# NPCX498S register map
File version: 1.0
Registers are 8-bit, read-write, reset 0x0 unless marked. A register's access mark holds for its fields unless they carry their own. Offsets are from the block's base; [hi:lo] are bit positions; {n}, {i} and the like mark numbered series.

## OTPI
Base 0x40007000
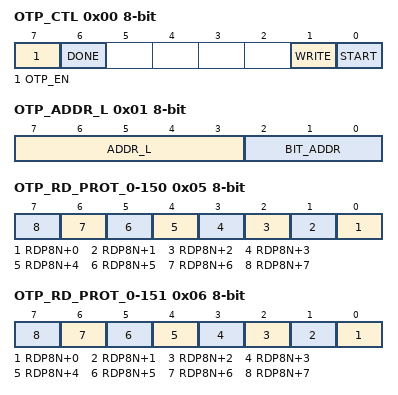
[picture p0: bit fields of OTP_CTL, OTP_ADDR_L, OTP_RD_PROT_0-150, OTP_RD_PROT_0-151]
0x00 OTP_CTL — OTP Control Register (OTP_CTL)
  [7] OTP_EN — OTPI Module Enable
  [6] DONE — OTP Operation Completed
  [1] WRITE — Write Select
  [0] START — Start OTP Operation
0x01 OTP_ADDR_L — OTP Address Low Register (OTP_ADDR_L)
  [7:3] ADDR_L — OTP Byte Address Low
  [2:0] BIT_ADDR — OTP Bit Address
0x02 OTP_ADDR_H — OTP Address High Register (OTP_ADDR_H)
  [5:0] ADDR_H — OTP Byte Address High
0x03 OTP_DOUT — OTP Read Data Register (OTP_DOUT)
0x05 OTP_RD_PROT_0-150 — OTP Read Protect 0-15 Register (OTP_RD_PROT_0-15)
  [n] RDP8N+{n} (n=0..7) — Read Protect Block 8*n+{n}
0x06 OTP_RD_PROT_0-151 — OTP Read Protect 0-15 Register (OTP_RD_PROT_0-15)
  [n] RDP8N+{n} (n=0..7) — Read Protect Block 8*n+{n}
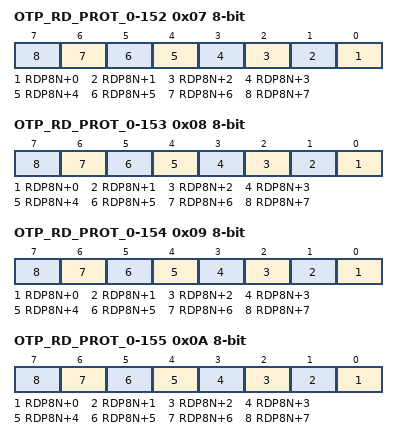
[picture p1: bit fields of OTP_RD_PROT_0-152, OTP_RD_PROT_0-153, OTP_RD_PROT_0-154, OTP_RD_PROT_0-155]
0x07 OTP_RD_PROT_0-152 — OTP Read Protect 0-15 Register (OTP_RD_PROT_0-15)
  [n] RDP8N+{n} (n=0..7) — Read Protect Block 8*n+{n}
0x08 OTP_RD_PROT_0-153 — OTP Read Protect 0-15 Register (OTP_RD_PROT_0-15)
  [n] RDP8N+{n} (n=0..7) — Read Protect Block 8*n+{n}
0x09 OTP_RD_PROT_0-154 — OTP Read Protect 0-15 Register (OTP_RD_PROT_0-15)
  [n] RDP8N+{n} (n=0..7) — Read Protect Block 8*n+{n}
0x0A OTP_RD_PROT_0-155 — OTP Read Protect 0-15 Register (OTP_RD_PROT_0-15)
  [n] RDP8N+{n} (n=0..7) — Read Protect Block 8*n+{n}
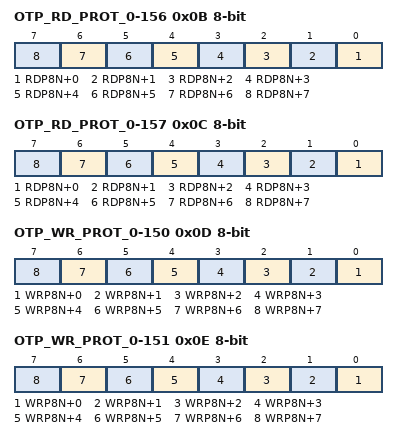
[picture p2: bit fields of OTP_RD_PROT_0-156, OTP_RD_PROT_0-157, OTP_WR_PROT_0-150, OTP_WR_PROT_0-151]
0x0B OTP_RD_PROT_0-156 — OTP Read Protect 0-15 Register (OTP_RD_PROT_0-15)
  [n] RDP8N+{n} (n=0..7) — Read Protect Block 8*n+{n}
0x0C OTP_RD_PROT_0-157 — OTP Read Protect 0-15 Register (OTP_RD_PROT_0-15)
  [n] RDP8N+{n} (n=0..7) — Read Protect Block 8*n+{n}
0x0D OTP_WR_PROT_0-150 — OTP Write Protect 0-15 Register (OTP_WR_PROT_0-15)
  [n] WRP8N+{n} (n=0..7) — Write Protect Block 8*n+{n}
0x0E OTP_WR_PROT_0-151 — OTP Write Protect 0-15 Register (OTP_WR_PROT_0-15)
  [n] WRP8N+{n} (n=0..7) — Write Protect Block 8*n+{n}
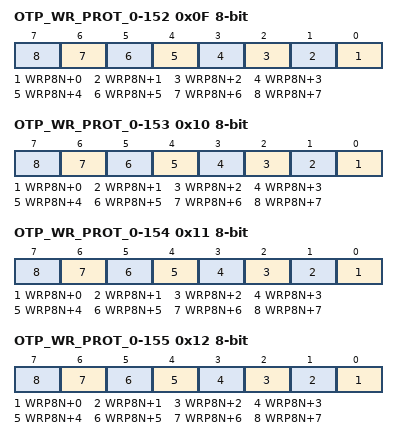
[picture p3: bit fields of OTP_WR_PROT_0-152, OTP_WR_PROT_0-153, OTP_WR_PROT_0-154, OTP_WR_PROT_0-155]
0x0F OTP_WR_PROT_0-152 — OTP Write Protect 0-15 Register (OTP_WR_PROT_0-15)
  [n] WRP8N+{n} (n=0..7) — Write Protect Block 8*n+{n}
0x10 OTP_WR_PROT_0-153 — OTP Write Protect 0-15 Register (OTP_WR_PROT_0-15)
  [n] WRP8N+{n} (n=0..7) — Write Protect Block 8*n+{n}
0x11 OTP_WR_PROT_0-154 — OTP Write Protect 0-15 Register (OTP_WR_PROT_0-15)
  [n] WRP8N+{n} (n=0..7) — Write Protect Block 8*n+{n}
0x12 OTP_WR_PROT_0-155 — OTP Write Protect 0-15 Register (OTP_WR_PROT_0-15)
  [n] WRP8N+{n} (n=0..7) — Write Protect Block 8*n+{n}
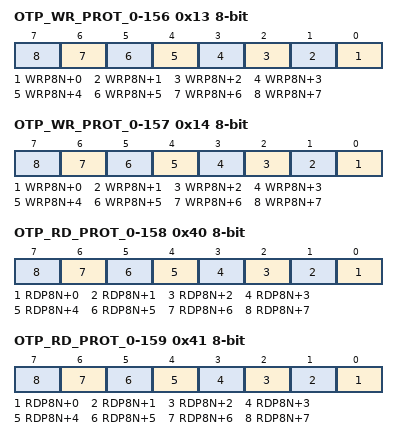
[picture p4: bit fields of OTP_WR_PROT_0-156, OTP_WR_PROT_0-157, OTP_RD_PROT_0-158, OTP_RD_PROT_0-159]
0x13 OTP_WR_PROT_0-156 — OTP Write Protect 0-15 Register (OTP_WR_PROT_0-15)
  [n] WRP8N+{n} (n=0..7) — Write Protect Block 8*n+{n}
0x14 OTP_WR_PROT_0-157 — OTP Write Protect 0-15 Register (OTP_WR_PROT_0-15)
  [n] WRP8N+{n} (n=0..7) — Write Protect Block 8*n+{n}
0x15 OTP_PRESC — OTP Prescaler Register (OTP_PRESC)
0x16 OTP_WRITE_EN0-30 — OTP Write Enable 0-3 Register (OTP_WRITE_EN0-3)
0x17 OTP_WRITE_EN0-31 — OTP Write Enable 0-3 Register (OTP_WRITE_EN0-3)
0x18 OTP_WRITE_EN0-32 — OTP Write Enable 0-3 Register (OTP_WRITE_EN0-3)
0x19 OTP_WRITE_EN0-33 — OTP Write Enable 0-3 Register (OTP_WRITE_EN0-3)
0x40 OTP_RD_PROT_0-158 — OTP Read Protect 0-15 Register (OTP_RD_PROT_0-15)
  [n] RDP8N+{n} (n=0..7) — Read Protect Block 8*n+{n}
0x41 OTP_RD_PROT_0-159 — OTP Read Protect 0-15 Register (OTP_RD_PROT_0-15)
  [n] RDP8N+{n} (n=0..7) — Read Protect Block 8*n+{n}
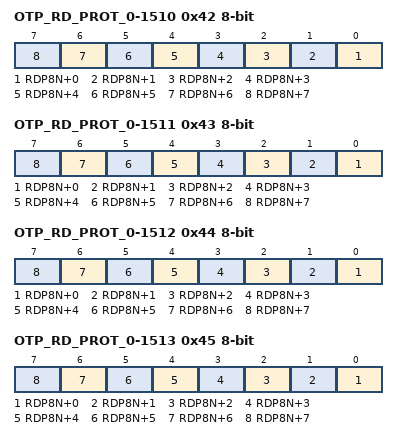
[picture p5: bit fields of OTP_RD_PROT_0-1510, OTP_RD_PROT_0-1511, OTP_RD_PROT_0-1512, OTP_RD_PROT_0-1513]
0x42 OTP_RD_PROT_0-1510 — OTP Read Protect 0-15 Register (OTP_RD_PROT_0-15)
  [n] RDP8N+{n} (n=0..7) — Read Protect Block 8*n+{n}
0x43 OTP_RD_PROT_0-1511 — OTP Read Protect 0-15 Register (OTP_RD_PROT_0-15)
  [n] RDP8N+{n} (n=0..7) — Read Protect Block 8*n+{n}
0x44 OTP_RD_PROT_0-1512 — OTP Read Protect 0-15 Register (OTP_RD_PROT_0-15)
  [n] RDP8N+{n} (n=0..7) — Read Protect Block 8*n+{n}
0x45 OTP_RD_PROT_0-1513 — OTP Read Protect 0-15 Register (OTP_RD_PROT_0-15)
  [n] RDP8N+{n} (n=0..7) — Read Protect Block 8*n+{n}
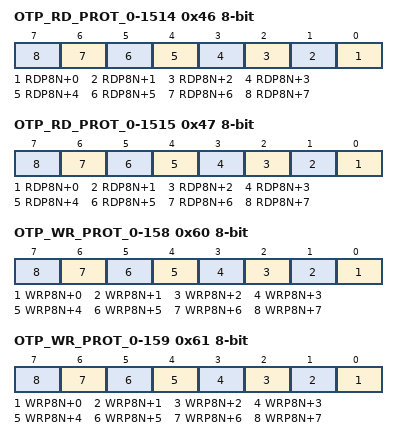
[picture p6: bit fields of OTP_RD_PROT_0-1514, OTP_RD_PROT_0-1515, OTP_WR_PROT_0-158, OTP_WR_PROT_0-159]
0x46 OTP_RD_PROT_0-1514 — OTP Read Protect 0-15 Register (OTP_RD_PROT_0-15)
  [n] RDP8N+{n} (n=0..7) — Read Protect Block 8*n+{n}
0x47 OTP_RD_PROT_0-1515 — OTP Read Protect 0-15 Register (OTP_RD_PROT_0-15)
  [n] RDP8N+{n} (n=0..7) — Read Protect Block 8*n+{n}
0x60 OTP_WR_PROT_0-158 — OTP Write Protect 0-15 Register (OTP_WR_PROT_0-15)
  [n] WRP8N+{n} (n=0..7) — Write Protect Block 8*n+{n}
0x61 OTP_WR_PROT_0-159 — OTP Write Protect 0-15 Register (OTP_WR_PROT_0-15)
  [n] WRP8N+{n} (n=0..7) — Write Protect Block 8*n+{n}
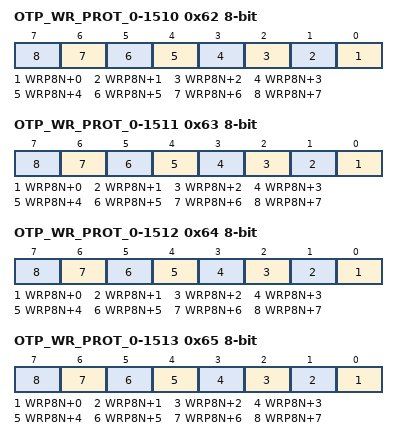
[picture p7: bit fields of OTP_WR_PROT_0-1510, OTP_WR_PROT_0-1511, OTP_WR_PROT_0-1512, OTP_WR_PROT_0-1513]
0x62 OTP_WR_PROT_0-1510 — OTP Write Protect 0-15 Register (OTP_WR_PROT_0-15)
  [n] WRP8N+{n} (n=0..7) — Write Protect Block 8*n+{n}
0x63 OTP_WR_PROT_0-1511 — OTP Write Protect 0-15 Register (OTP_WR_PROT_0-15)
  [n] WRP8N+{n} (n=0..7) — Write Protect Block 8*n+{n}
0x64 OTP_WR_PROT_0-1512 — OTP Write Protect 0-15 Register (OTP_WR_PROT_0-15)
  [n] WRP8N+{n} (n=0..7) — Write Protect Block 8*n+{n}
0x65 OTP_WR_PROT_0-1513 — OTP Write Protect 0-15 Register (OTP_WR_PROT_0-15)
  [n] WRP8N+{n} (n=0..7) — Write Protect Block 8*n+{n}
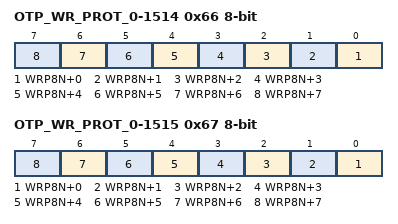
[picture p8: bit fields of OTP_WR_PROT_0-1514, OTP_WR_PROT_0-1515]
0x66 OTP_WR_PROT_0-1514 — OTP Write Protect 0-15 Register (OTP_WR_PROT_0-15)
  [n] WRP8N+{n} (n=0..7) — Write Protect Block 8*n+{n}
0x67 OTP_WR_PROT_0-1515 — OTP Write Protect 0-15 Register (OTP_WR_PROT_0-15)
  [n] WRP8N+{n} (n=0..7) — Write Protect Block 8*n+{n}
